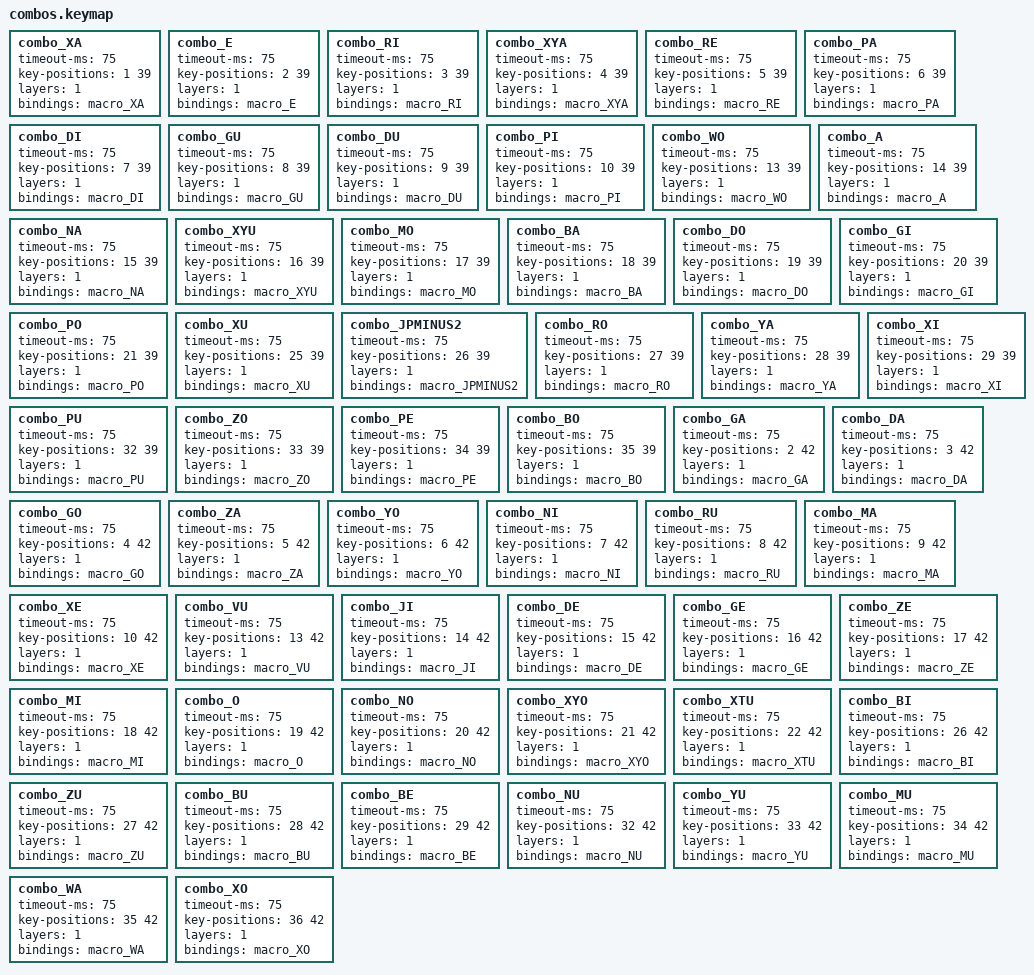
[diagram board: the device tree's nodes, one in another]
        combo_XA {
                timeout-ms = <75>;
                key-positions = <1 39>;
                layers = <1>;
                bindings = <&macro_XA>;
        };

        combo_E {
                timeout-ms = <75>;
                key-positions = <2 39>;
                layers = <1>;
                bindings = <&macro_E>;
        };

        combo_RI {
                timeout-ms = <75>;
                key-positions = <3 39>;
                layers = <1>;
                bindings = <&macro_RI>;
        };

        combo_XYA {
                timeout-ms = <75>;
                key-positions = <4 39>;
                layers = <1>;
                bindings = <&macro_XYA>;
        };

        combo_RE {
                timeout-ms = <75>;
                key-positions = <5 39>;
                layers = <1>;
                bindings = <&macro_RE>;
        };

        combo_PA {
                timeout-ms = <75>;
                key-positions = <6 39>;
                layers = <1>;
                bindings = <&macro_PA>;
        };

        combo_DI {
                timeout-ms = <75>;
                key-positions = <7 39>;
                layers = <1>;
                bindings = <&macro_DI>;
        };

        combo_GU {
                timeout-ms = <75>;
                key-positions = <8 39>;
                layers = <1>;
                bindings = <&macro_GU>;
        };

        combo_DU {
                timeout-ms = <75>;
                key-positions = <9 39>;
                layers = <1>;
                bindings = <&macro_DU>;
        };

        combo_PI {
                timeout-ms = <75>;
                key-positions = <10 39>;
                layers = <1>;
                bindings = <&macro_PI>;
        };

        combo_WO {
                timeout-ms = <75>;
                key-positions = <13 39>;
                layers = <1>;
                bindings = <&macro_WO>;
        };

        combo_A {
                timeout-ms = <75>;
                key-positions = <14 39>;
                layers = <1>;
                bindings = <&macro_A>;
        };

        combo_NA {
                timeout-ms = <75>;
                key-positions = <15 39>;
                layers = <1>;
                bindings = <&macro_NA>;
        };

        combo_XYU {
                timeout-ms = <75>;
                key-positions = <16 39>;
                layers = <1>;
                bindings = <&macro_XYU>;
        };

        combo_MO {
                timeout-ms = <75>;
                key-positions = <17 39>;
                layers = <1>;
                bindings = <&macro_MO>;
        };

        combo_BA {
                timeout-ms = <75>;
                key-positions = <18 39>;
                layers = <1>;
                bindings = <&macro_BA>;
        };

        combo_DO {
                timeout-ms = <75>;
                key-positions = <19 39>;
                layers = <1>;
                bindings = <&macro_DO>;
        };

        combo_GI {
                timeout-ms = <75>;
                key-positions = <20 39>;
                layers = <1>;
                bindings = <&macro_GI>;
        };

        combo_PO {
                timeout-ms = <75>;
                key-positions = <21 39>;
                layers = <1>;
                bindings = <&macro_PO>;
        };

        combo_XU {
                timeout-ms = <75>;
                key-positions = <25 39>;
                layers = <1>;
                bindings = <&macro_XU>;
        };

        combo_JPMINUS2 {
                timeout-ms = <75>;
                key-positions = <26 39>;
                layers = <1>;
                bindings = <&macro_JPMINUS2>;
        };

        combo_RO {
                timeout-ms = <75>;
                key-positions = <27 39>;
                layers = <1>;
                bindings = <&macro_RO>;
        };

        combo_YA {
                timeout-ms = <75>;
                key-positions = <28 39>;
                layers = <1>;
                bindings = <&macro_YA>;
        };

        combo_XI {
                timeout-ms = <75>;
                key-positions = <29 39>;
                layers = <1>;
                bindings = <&macro_XI>;
        };

        combo_PU {
                timeout-ms = <75>;
                key-positions = <32 39>;
                layers = <1>;
                bindings = <&macro_PU>;
        };

        combo_ZO {
                timeout-ms = <75>;
                key-positions = <33 39>;
                layers = <1>;
                bindings = <&macro_ZO>;
        };

        combo_PE {
                timeout-ms = <75>;
                key-positions = <34 39>;
                layers = <1>;
                bindings = <&macro_PE>;
        };

        combo_BO {
                timeout-ms = <75>;
                key-positions = <35 39>;
                layers = <1>;
                bindings = <&macro_BO>;
        };

        combo_GA {
                timeout-ms = <75>;
                key-positions = <2 42>;
                layers = <1>;
                bindings = <&macro_GA>;
        };

        combo_DA {
                timeout-ms = <75>;
                key-positions = <3 42>;
                layers = <1>;
                bindings = <&macro_DA>;
        };

        combo_GO {
                timeout-ms = <75>;
                key-positions = <4 42>;
                layers = <1>;
                bindings = <&macro_GO>;
        };

        combo_ZA {
                timeout-ms = <75>;
                key-positions = <5 42>;
                layers = <1>;
                bindings = <&macro_ZA>;
        };

        combo_YO {
                timeout-ms = <75>;
                key-positions = <6 42>;
                layers = <1>;
                bindings = <&macro_YO>;
        };

        combo_NI {
                timeout-ms = <75>;
                key-positions = <7 42>;
                layers = <1>;
                bindings = <&macro_NI>;
        };

        combo_RU {
                timeout-ms = <75>;
                key-positions = <8 42>;
                layers = <1>;
                bindings = <&macro_RU>;
        };

        combo_MA {
                timeout-ms = <75>;
                key-positions = <9 42>;
                layers = <1>;
                bindings = <&macro_MA>;
        };

        combo_XE {
                timeout-ms = <75>;
                key-positions = <10 42>;
                layers = <1>;
                bindings = <&macro_XE>;
        };

        combo_VU {
                timeout-ms = <75>;
                key-positions = <13 42>;
                layers = <1>;
                bindings = <&macro_VU>;
        };

        combo_JI {
                timeout-ms = <75>;
                key-positions = <14 42>;
                layers = <1>;
                bindings = <&macro_JI>;
        };

        combo_DE {
                timeout-ms = <75>;
                key-positions = <15 42>;
                layers = <1>;
                bindings = <&macro_DE>;
        };

        combo_GE {
                timeout-ms = <75>;
                key-positions = <16 42>;
                layers = <1>;
                bindings = <&macro_GE>;
        };

        combo_ZE {
                timeout-ms = <75>;
                key-positions = <17 42>;
                layers = <1>;
                bindings = <&macro_ZE>;
        };

        combo_MI {
                timeout-ms = <75>;
                key-positions = <18 42>;
                layers = <1>;
                bindings = <&macro_MI>;
        };

        combo_O {
                timeout-ms = <75>;
                key-positions = <19 42>;
                layers = <1>;
                bindings = <&macro_O>;
        };

        combo_NO {
                timeout-ms = <75>;
                key-positions = <20 42>;
                layers = <1>;
                bindings = <&macro_NO>;
        };

        combo_XYO {
                timeout-ms = <75>;
                key-positions = <21 42>;
                layers = <1>;
                bindings = <&macro_XYO>;
        };

        combo_XTU {
                timeout-ms = <75>;
                key-positions = <22 42>;
                layers = <1>;
                bindings = <&macro_XTU>;
        };

        combo_BI {
                timeout-ms = <75>;
                key-positions = <26 42>;
                layers = <1>;
                bindings = <&macro_BI>;
        };

        combo_ZU {
                timeout-ms = <75>;
                key-positions = <27 42>;
                layers = <1>;
                bindings = <&macro_ZU>;
        };

        combo_BU {
                timeout-ms = <75>;
                key-positions = <28 42>;
                layers = <1>;
                bindings = <&macro_BU>;
        };

        combo_BE {
                timeout-ms = <75>;
                key-positions = <29 42>;
                layers = <1>;
                bindings = <&macro_BE>;
        };

        combo_NU {
                timeout-ms = <75>;
                key-positions = <32 42>;
                layers = <1>;
                bindings = <&macro_NU>;
        };

        combo_YU {
                timeout-ms = <75>;
                key-positions = <33 42>;
                layers = <1>;
                bindings = <&macro_YU>;
        };

        combo_MU {
                timeout-ms = <75>;
                key-positions = <34 42>;
                layers = <1>;
                bindings = <&macro_MU>;
        };

        combo_WA {
                timeout-ms = <75>;
                key-positions = <35 42>;
                layers = <1>;
                bindings = <&macro_WA>;
        };

        combo_XO {
                timeout-ms = <75>;
                key-positions = <36 42>;
                layers = <1>;
                bindings = <&macro_XO>;
        };
